# STM32H7P4xx register map
File version: 1.0
Registers are 32-bit, read-write, reset 0x0 unless marked. A register's access mark holds for its fields unless they carry their own. Offsets are from the block's base; [hi:lo] are bit positions; lines under a group give offsets from that group; {n}, {i} and the like mark numbered series.

## I3C1 — Improved Inter-integrated Circuit Interface
Base 0x40006000
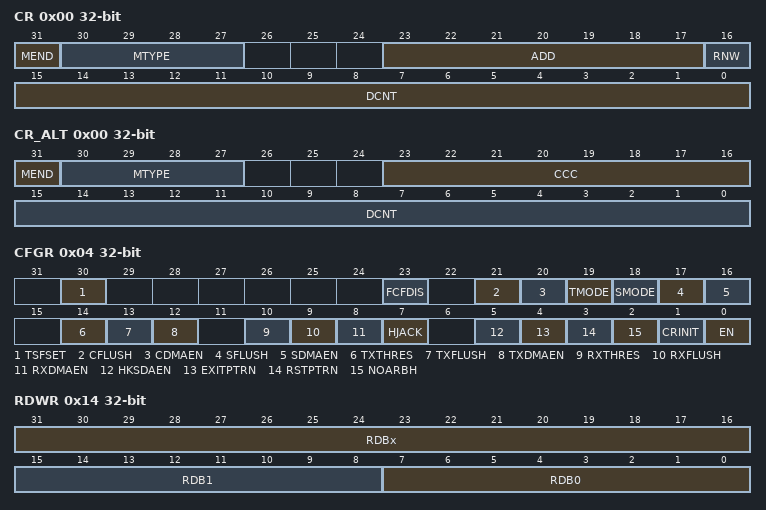
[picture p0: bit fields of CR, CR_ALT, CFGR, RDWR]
0x00 CR — I3C message Control register
  [31] MEND — Message end type/last message of a frame
  [30:27] MTYPE — Message Type
  [23:17] ADD — 7-bit I3C dynamic
  [16] RNW — Read / non-write message
  [15:0] DCNT — Count of data to transfer during a read or write message
0x00 CR_ALT (alternate view of CR) — I3C message Control register
  [31] MEND — Message end type/last message of a frame
  [30:27] MTYPE — Message Type
  [23:16] CCC — 8-Bit CCC code
  [15:0] DCNT — Count of data to transfer during a read or write message
0x04 CFGR — I3C Configuration register
  [30] TSFSET — Frame transfer set
  [23] FCFDIS — FCF generation disable
  [21] CFLUSH — C-FIFO flush
  [20] CDMAEN — C-FIFO DMA request enable
  [19] TMODE — Transmit mode
  [18] SMODE — S-FIFO enable / status receive mode
  [17] SFLUSH — S-FIFO flush
  [16] SDMAEN — S-FIFO DMA request enable
  [14] TXTHRES — TX-FIFO threshold
  [13] TXFLUSH — TX-FIFO flush
  [12] TXDMAEN — TX-FIFO DMA request enable
  [10] RXTHRES — RX-FIFO threshold
  [9] RXFLUSH — RX-FIFO flush
  [8] RXDMAEN — RX-FIFO DMA request enable
  [7] HJACK — Hot-join request acknowledge
  [5] HKSDAEN — High-keeper enable on SDA line
  [4] EXITPTRN — HDR exit pattern enable
  [3] RSTPTRN — HDR reset pattern enable
  [2] NOARBH — No arbitrable header after a start
  [1] CRINIT — Initial controller/target role
  [0] EN — I3C enable
0x10 RDR ro — I3C Received Data byte register
  [7:0] RDB0 — 8-bit received data on I3C bus
0x14 RDWR ro — I3C Received Data Word register
  [31:16] RDBx — Receive Data Byte, full double word
  [15:8] RDB1 — 8-bit received data (next byte after RDB0 on I3C bus)
  [7:0] RDB0 — 8-bit received data (earliest byte on I3C bus)
0x18 TDR — I3C Transmit Data byte register
  [7:0] TDB0 — 8-bit data to transmit on I3C bus
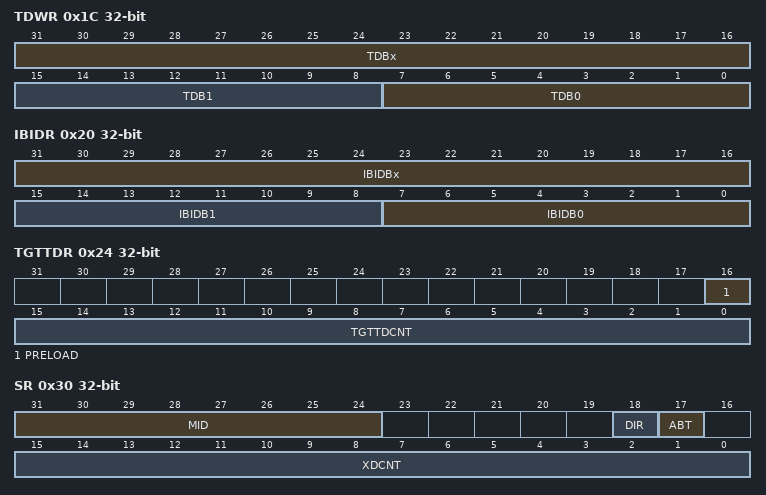
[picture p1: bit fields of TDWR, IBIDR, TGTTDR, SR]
0x1C TDWR — I3C Transmit Data Word register
  [31:16] TDBx — Transmit Data Byte, full double word
  [15:8] TDB1 — 8-bit transmit data (next byte after TDB0[7:0] on I3C bus)
  [7:0] TDB0 — 8-bit transmit data (earliest byte on I3C bus)
0x20 IBIDR — I3C IBI payload Data register
  [31:16] IBIDBx — IBI Data Byte, full double word
  [15:8] IBIDB1 — 8-bit IBI payload data (next byte on I3C bus after IBIDB0[7:0])
  [7:0] IBIDB0 — 8-bit IBI payload data (earliest byte on I3C bus, MDB[7:0] mandatory data byte)
0x24 TGTTDR — I3C Target Transmit configuration register
  [16] PRELOAD — Preload of the TX-FIFO
  [15:0] TGTTDCNT — Transmit data counter, in bytes
0x30 SR ro — I3C Status register
  [31:24] MID — Message identifier/counter of a given frame
  [18] DIR — Message Direction
  [17] ABT — A private read message is ended prematurely by the target
  [15:0] XDCNT — Data counter
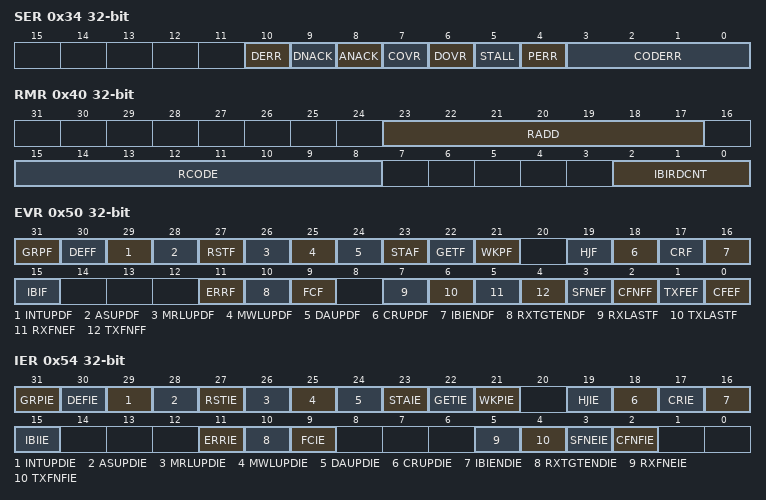
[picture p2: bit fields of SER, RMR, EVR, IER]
0x34 SER ro — I3C Status Error register
  [10] DERR — Data error
  [9] DNACK — Data not acknowledged
  [8] ANACK — Address not acknowledged
  [7] COVR — C-FIFO underrun or S-FIFO overrun
  [6] DOVR — RX-FIFO overrun or TX-FIFO underrun
  [5] STALL — SCL stall error
  [4] PERR — Protocol error
  [3:0] CODERR — Protocol error code/type
0x40 RMR ro — I3C Received Message register
  [23:17] RADD — Received target address
  [15:8] RCODE — Received CCC code
  [2:0] IBIRDCNT — IBI received payload data count
0x50 EVR ro — I3C Event register
  [31] GRPF — Group addressing flag
  [30] DEFF — DEFTGTS flag
  [29] INTUPDF — Interrupt/controller-role/hot-join update flag
  [28] ASUPDF — Activity state update flag
  [27] RSTF — Reset pattern flag
  [26] MRLUPDF — Maximum Read Length Update Flag
  [25] MWLUPDF — Maximum Write Length Update Flag
  [24] DAUPDF — Dynamic Address Update Flag
  [23] STAF — Get Status Flag
  [22] GETF — Get flag
  [21] WKPF — Wake-up/missed start flag
  [19] HJF — Hot-join Flag
  [18] CRUPDF — Controller-role Update Flag
  [17] CRF — Controller-role Request Flag
  [16] IBIENDF — IBI End Flag
  [15] IBIF — IBI Flag
  [11] ERRF — Flag
  [10] RXTGTENDF — Target-initiated read end flag
  [9] FCF — Frame Complete Flag
  [7] RXLASTF — Last read data byte/word flag
  [6] TXLASTF — Last written data byte/word flag
  [5] RXFNEF — RX-FIFO not empty flag
  [4] TXFNFF — TX-FIFO not full flag
  [3] SFNEF — S-FIFO not empty flag
  [2] CFNFF — C-FIFO not full flag
  [1] TXFEF — TX-FIFO empty flag
  [0] CFEF — C-FIFO empty flag
0x54 IER — I3C Interrupt Enable register
  [31] GRPIE — DEFGRPA CCC interrupt enable
  [30] DEFIE — DEFTGTS CCC interrupt enable
  [29] INTUPDIE — ENEC/DISEC CCC interrupt enable
  [28] ASUPDIE — ENTASx CCC interrupt enable
  [27] RSTIE — reset pattern interrupt enable
  [26] MRLUPDIE — SETMRL CCC interrupt enable
  [25] MWLUPDIE — SETMWL CCC interrupt enable
  [24] DAUPDIE — ENTDAA/RSTDAA/SETNEWDA CCC interrupt enable
  [23] STAIE — format 1 GETSTATUS CCC interrupt enable
  [22] GETIE — GETxxx CCC interrupt enable
  [21] WKPIE — Wake-Up Interrupt Enable
  [19] HJIE — Hot-join Interrupt Enable
  [18] CRUPDIE — Controller-role Update Interrupt Enable
  [17] CRIE — Controller-role request interrupt enable
  [16] IBIENDIE — IBI End Interrupt Enable
  [15] IBIIE — IBI request interrupt enable
  [11] ERRIE — Error Interrupt Enable
  [10] RXTGTENDIE — target-initiated read end interrupt enable
  [9] FCIE — Frame Complete Interrupt Enable
  [5] RXFNEIE — RX-FIFO not empty interrupt enable
  [4] TXFNFIE — TX-FIFO not full interrupt enable
  [3] SFNEIE — S-FIFO not empty interrupt enable when the I3C acts as controller
  [2] CFNFIE — C-FIFO not full interrupt enable when the I3C acts as controller
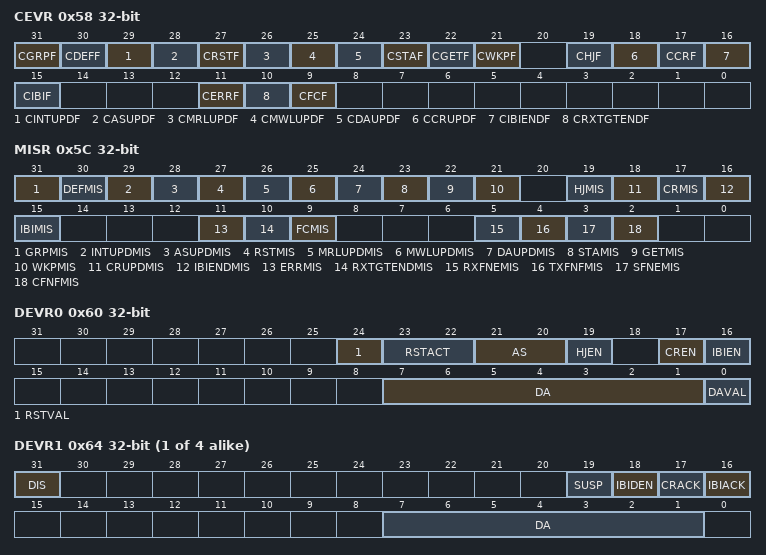
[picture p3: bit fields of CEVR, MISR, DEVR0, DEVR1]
0x58 CEVR — I3C Clear Event register
  [31] CGRPF — Clear DEFGRPA CCC flag
  [30] CDEFF — Clear DEFTGTS CCC flag
  [29] CINTUPDF — Clear ENEC/DISEC CCC flag
  [28] CASUPDF — Clear ENTASx CCC flag
  [27] CRSTF — Clear reset pattern flag
  [26] CMRLUPDF — Clear SETMRL CCC flag
  [25] CMWLUPDF — Clear SETMWL CCC flag
  [24] CDAUPDF — Clear ENTDAA/RSTDAA/SETNEWDA CCC flag
  [23] CSTAF — Clear format 1 GETSTATUS CCC flag
  [22] CGETF — Clear GETxxx CCC flag
  [21] CWKPF — Clear wake-up flag
  [19] CHJF — Clear hot-join flag
  [18] CCRUPDF — Clear controller-role update flag
  [17] CCRF — Clear controller-role request flag
  [16] CIBIENDF — Clear IBI end flag
  [15] CIBIF — Clear IBI request flag
  [11] CERRF — Clear error flag
  [10] CRXTGTENDF — Clear target-initiated read end flag
  [9] CFCF — Clear frame complete flag
0x5C MISR ro — I3C Masked Interrupt Status register
  [31] GRPMIS — DEFGRPA CCC masked interrupt status
  [30] DEFMIS — DEFTGTS CCC masked interrupt status
  [29] INTUPDMIS — ENEC/DISEC CCC masked interrupt status
  [28] ASUPDMIS — ENTASx CCC masked interrupt status
  [27] RSTMIS — reset pattern masked interrupt status
  [26] MRLUPDMIS — SETMRL CCC masked interrupt status
  [25] MWLUPDMIS — SETMWL CCC masked interrupt status
  [24] DAUPDMIS — ENTDAA/RSTDAA/SETNEWDA CCC masked interrupt status
  [23] STAMIS — format 1 GETSTATUS CCC masked interrupt status
  [22] GETMIS — GETxxx CCC masked interrupt status, except GETSTATUS of format 1
  [21] WKPMIS — Wake-up/missed start masked interrupt status
  [19] HJMIS — Hot-join masked interrupt status
  [18] CRUPDMIS — Controller-role update masked interrupt status
  [17] CRMIS — Controller-role request masked interrupt status
  [16] IBIENDMIS — IBI end masked interrupt status
  [15] IBIMIS — IBI request masked interrupt status
  [11] ERRMIS — error masked interrupt status
  [10] RXTGTENDMIS — target-initiated read end masked interrupt status
  [9] FCMIS — frame complete masked interrupt status
  [5] RXFNEMIS — RX-FIFO not empty masked interrupt status
  [4] TXFNFMIS — TX-FIFO not full masked interrupt status
  [3] SFNEMIS — S-FIFO not empty masked interrupt status
  [2] CFNFMIS — C-FIFO not full masked interrupt status
0x60 DEVR0 — I3C own device characteristics register
  [24] RSTVAL — Reset action is valid
  [23:22] RSTACT — Reset action/level on received reset pattern
  [21:20] AS — Activity state
  [19] HJEN — Hot-join request enable
  [17] CREN — Controller-role request enable
  [16] IBIEN — IBI request enable
  [7:1] DA — 7-bit dynamic address
  [0] DAVAL — Dynamic address is valid
{0x60+4i} DEVR{i} (i=1..4) — I3C device x (1<=x<=4) register
  [31] DIS — Disables writes to DA[6:0]
  [19] SUSP — Suspend/stop I3C transfer on received IBI
  [18] IBIDEN — IBI data enable
  [17] CRACK — Controller-role request acknowledge
  [16] IBIACK — IBI request acknowledge
  [7:1] DA — Assigned I3C dynamic address to target x
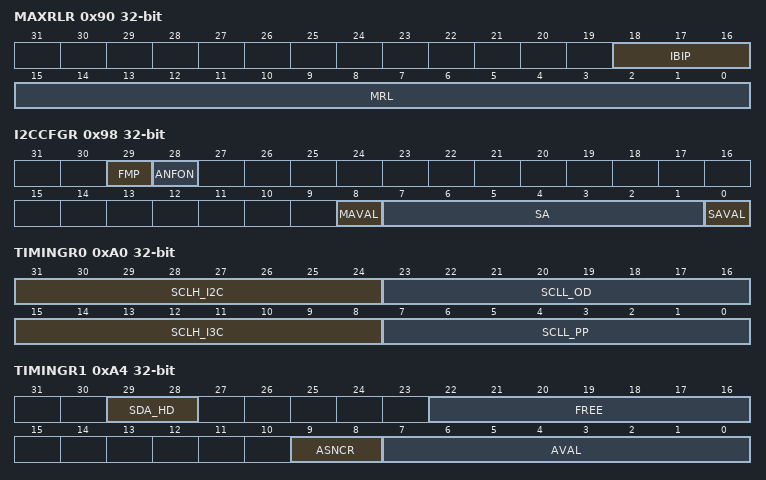
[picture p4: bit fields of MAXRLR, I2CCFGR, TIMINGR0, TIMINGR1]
0x90 MAXRLR — I3C Maximum Read Length register
  [18:16] IBIP — IBI payload data maximum size, in bytes
  [15:0] MRL — Maximum data read length
0x94 MAXWLR — I3C Maximum Write Length register
  [15:0] MWL — Maximum data write length
0x98 I2CCFGR — I3C IC target configuration register
  [29] FMP — high drive enable for Fast Mode plus
  [28] ANFON — analog filter enable
  [8] MAVAL — Minimum I3C target address 7'h01 is valid
  [7:1] SA — 7-bit static address
  [0] SAVAL — Static address is valid
0xA0 TIMINGR0 — I3C Timing register 0
  [31:24] SCLH_I2C — SCL high duration, used for legacy I2C messages
  [23:16] SCLL_OD — SCL low duration in open-drain phases
  [15:8] SCLH_I3C — SCL high duration, used for I3C messages
  [7:0] SCLL_PP — SCL Low duration in I3C Push-Pull phases
0xA4 TIMINGR1 — I3C Timing register 1
  [29:28] SDA_HD — SDA hold time
  [22:16] FREE — Number of kernel clocks cycles that is used to set some MIPI timings like bus free condition time
  [9:8] ASNCR — Activity State of the New Controller
  [7:0] AVAL — Number of kernel clock cycles to set a time unit of 1us
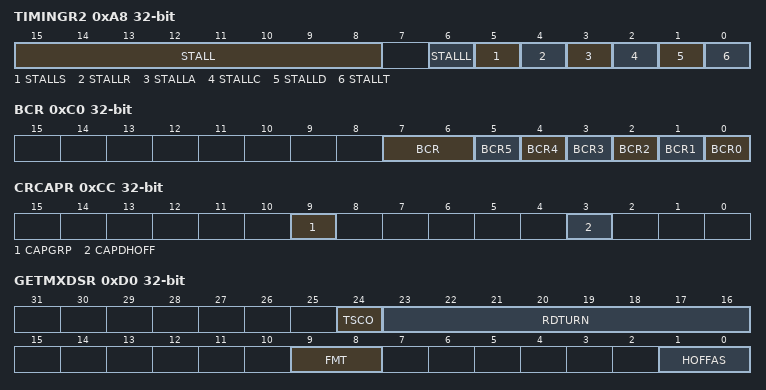
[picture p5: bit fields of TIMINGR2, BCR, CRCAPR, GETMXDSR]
0xA8 TIMINGR2 — I3C Timing register 2
  [15:8] STALL — Controller clock stall time
  [6] STALLL — Controller clock stall enable in the address ACK/NACK phase of a legacy I2C read/write message
  [5] STALLS — Controller clock stall enable in the data ACK/NACK phase of a legacy I2C write message
  [4] STALLR — Controller clock stall enable in the data ACK/NACK phase of a legacy I2C read message
  [3] STALLA — Controller clock stall enable on ACK phase
  [2] STALLC — Controller clock stall enable on PAR phase of CCC
  [1] STALLD — Controller clock stall enable on PAR phase of Data
  [0] STALLT — Controller clock stall enable on T-bit phase of data
0xC0 BCR — I3C Bus Characteristics register
  [7:6] BCR — Bus Characteristics
  [5] BCR5 — Advanced capabilities
  [4] BCR4 — Virtual target support
  [3] BCR3 — Offline capable
  [2] BCR2 — in-band interrupt (IBI) payload
  [1] BCR1 — IBI Request capable
  [0] BCR0 — max data speed limitation
0xC4 DCR — I3C Device Characteristics register
  [7:0] DCR — Devices Characteristics ID
0xC8 GETCAPR — I3C GET CAPabilities register
  [14] CAPPEND — IBI MDB support for pending read notification
0xCC CRCAPR — I3C Controller CAPabilities register
  [9] CAPGRP — group management support
  [3] CAPDHOFF — delayed controller-role hand-off
0xD0 GETMXDSR — I3C GET Max Data Speed register
  [24] TSCO — clock-to-data turnaround time
  [23:16] RDTURN — programmed byte of the 3-byte MaxRdTurn
  [9:8] FMT — GETMXDS CCC format
  [1:0] HOFFAS — Controller hand-off activity state
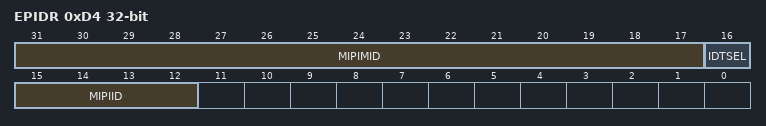
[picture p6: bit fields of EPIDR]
0xD4 EPIDR — I3C Extended Provisioned ID register
  [31:17] MIPIMID — 15-bit MIPI manufacturer ID
  [16] IDTSEL — provisioned ID type selector
  [15:12] MIPIID — 4-bit MIPI Instance ID
